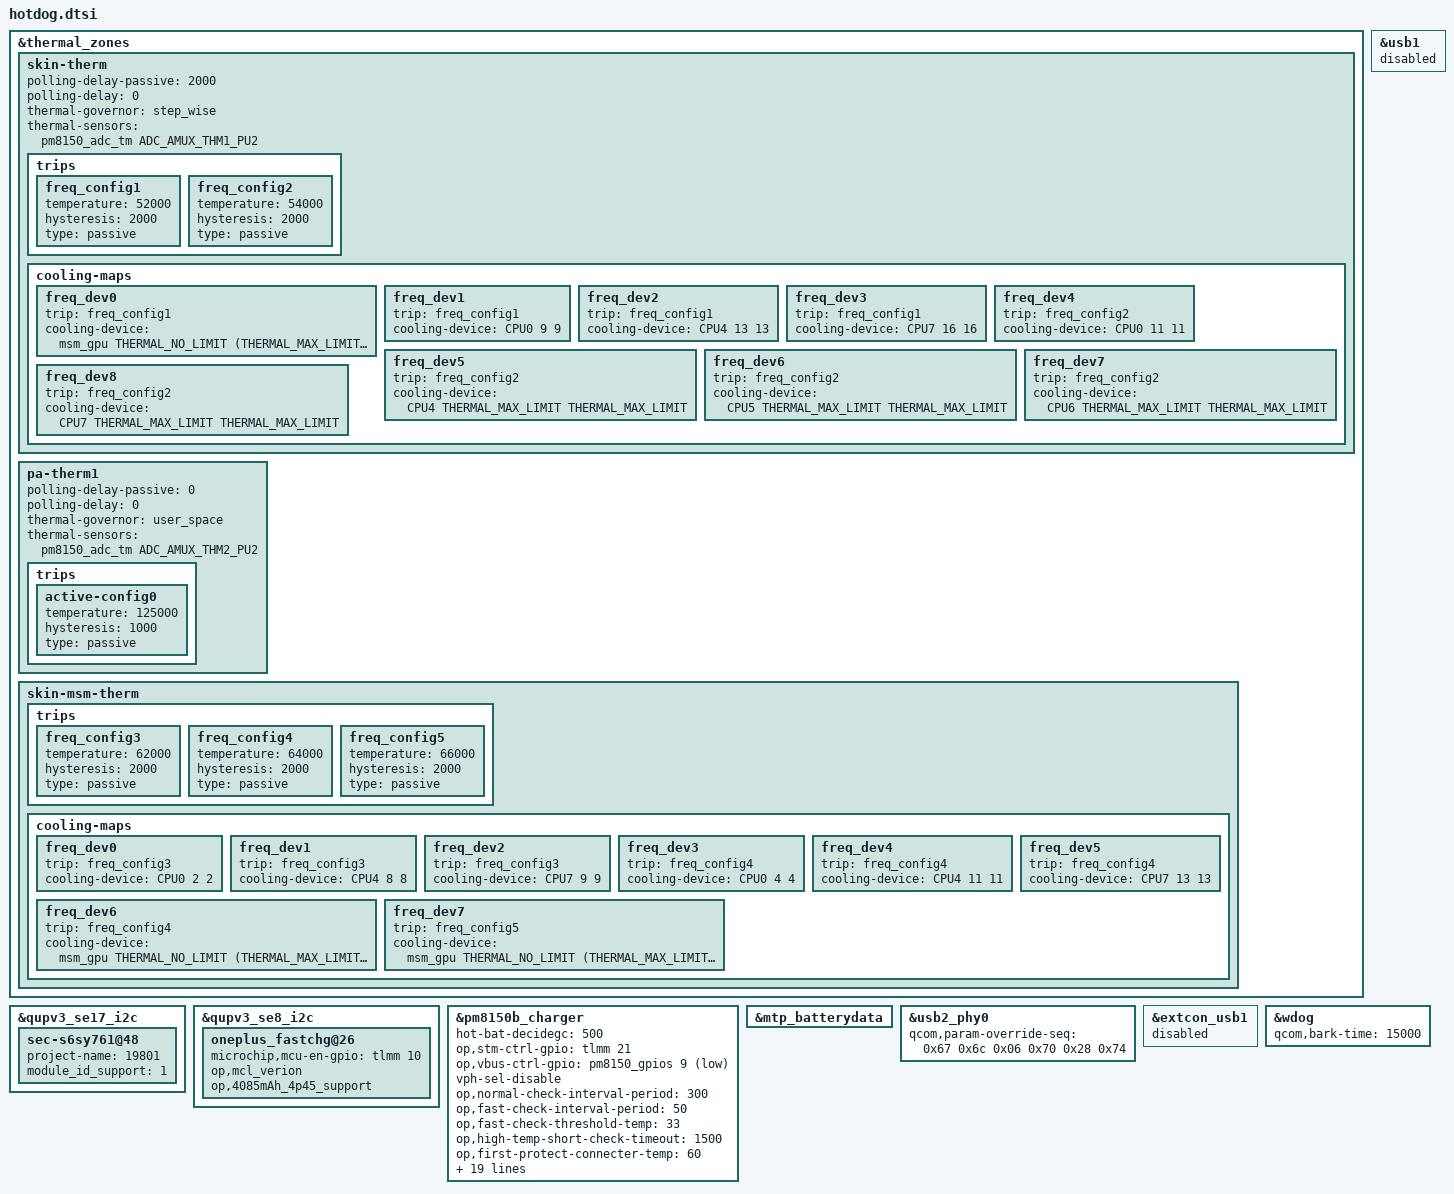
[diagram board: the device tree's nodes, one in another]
/*this is for different project dtsi*/
/* OnePlus add thermistor, by rio.zhao*/

&thermal_zones {
	skin-therm {
		polling-delay-passive = <2000>;
		polling-delay = <0>;
		thermal-governor = "step_wise";
		thermal-sensors = <&pm8150_adc_tm ADC_AMUX_THM1_PU2>;
		trips {
			freq_config1: freq_config1 {
				temperature = <52000>;
				hysteresis = <2000>;
				type = "passive";
			};
			freq_config2: freq_config2 {
				temperature = <54000>;
				hysteresis = <2000>;
				type = "passive";
			};
		};
		cooling-maps {
			freq_dev0 {
				trip = <&freq_config1>;
				cooling-device =
					<&msm_gpu THERMAL_NO_LIMIT
						(THERMAL_MAX_LIMIT-1)>;/*345*/
			};
			freq_dev1 {
				trip = <&freq_config1>;
				cooling-device =
					<&CPU0 9 9>;/*1036*/
			};
			freq_dev2 {
				trip = <&freq_config1>;
				cooling-device =
					<&CPU4 13 13>;/*1056*/
			};
			freq_dev3 {
				trip = <&freq_config1>;
				cooling-device =
					<&CPU7 16 16>;/*1171*/
			};
			freq_dev4 {
				trip = <&freq_config2>;
				cooling-device =
					<&CPU0 11 11>;/*844*/
			};
			freq_dev5 {
				trip = <&freq_config2>;
				cooling-device =
					<&CPU4 THERMAL_MAX_LIMIT
					THERMAL_MAX_LIMIT>;
			};
			freq_dev6 {
				trip = <&freq_config2>;
				cooling-device =
					<&CPU5 THERMAL_MAX_LIMIT
					THERMAL_MAX_LIMIT>;
			};
			freq_dev7 {
				trip = <&freq_config2>;
				cooling-device =
					<&CPU6 THERMAL_MAX_LIMIT
					THERMAL_MAX_LIMIT>;
			};
			freq_dev8 {
				trip = <&freq_config2>;
				cooling-device =
					<&CPU7 THERMAL_MAX_LIMIT
					THERMAL_MAX_LIMIT>;
			};
		};
	};

	pa-therm1 {
		polling-delay-passive = <0>;
		polling-delay = <0>;
		thermal-governor = "user_space";
		thermal-sensors = <&pm8150_adc_tm ADC_AMUX_THM2_PU2>;
		trips {
			active-config0 {
				temperature = <125000>;
				hysteresis = <1000>;
				type = "passive";
			};
		};
	};

	skin-msm-therm {
		trips {
			freq_config3: freq_config3 {
				temperature = <62000>;
				hysteresis = <2000>;
				type = "passive";
			};
			freq_config4: freq_config4 {
				temperature = <64000>;
				hysteresis = <2000>;
				type = "passive";
			};
			freq_config5: freq_config5 {
				temperature = <66000>;
				hysteresis = <2000>;
				type = "passive";
			};
		};
		cooling-maps {
			freq_dev0 {
				trip = <&freq_config3>;
				cooling-device =
					<&CPU0 2 2>;/*1632 18*/
			};
			freq_dev1 {
				trip = <&freq_config3>;
				cooling-device =
					<&CPU4 8 8>;/*1612 17*/
			};
			freq_dev2 {
				trip = <&freq_config3>;
				cooling-device =
					<&CPU7 9 9>;/*1920 20*/
			};
			freq_dev3 {
				trip = <&freq_config4>;
				cooling-device =
					<&CPU0 4 4>;/*1478*/
			};
			freq_dev4 {
				trip = <&freq_config4>;
				cooling-device =
					<&CPU4 11 11>;/*1286*/
			};
			freq_dev5 {
				trip = <&freq_config4>;
				cooling-device =
					<&CPU7 13 13>;/*1497*/
			};
			freq_dev6 {
				trip = <&freq_config4>;
				cooling-device =
					<&msm_gpu THERMAL_NO_LIMIT
						(THERMAL_MAX_LIMIT-3)>;/*499*/
			};
			freq_dev7 {
				trip = <&freq_config5>;
				cooling-device =
					<&msm_gpu THERMAL_NO_LIMIT
						(THERMAL_MAX_LIMIT-2)>;/*427*/
			};
		};
	};
};

&qupv3_se17_i2c {
	sec-s6sy761@48 {
		project-name = "19801";
		module_id_support = <1>;
	};
};

/* for Battery & Charging  STRAT */
&qupv3_se8_i2c {
	oneplus_fastchg@26{
		microchip,mcu-en-gpio = <&tlmm 10 0x00>;
		op,mcl_verion;
		op,4085mAh_4p45_support;
	};
};

&pm8150b_charger {
	/* for verify test adjust 530->500 */
	hot-bat-decidegc = <500>;
	/* for external ship mode suppot */
	op,stm-ctrl-gpio = <&tlmm 21 0x00>;
	op,vbus-ctrl-gpio = <&pm8150_gpios 9 GPIO_ACTIVE_LOW>;

	/*not need vph sel 300mv for LCD DCDC mode switch issue*/
	vph-sel-disable;

	/* for usb connecter temperature check */
	op,normal-check-interval-period = <300>;
	op,fast-check-interval-period = <50>;
	op,fast-check-threshold-temp = <33>;
	op,high-temp-short-check-timeout = <1500>;
	op,first-protect-connecter-temp = <60>;
	op,second-protect-connecter-temp = <45>;
	op,second-protect-interval-temp = <12>;
	op,third-protect-rise-rate = <3>;
	op,third-protect-loop-temp = <40>;
	op,third-protect-interval-temp = <8>;
	op,third-protect-base-temp = <20>;

	/* for charge current&voltage curve optimize */
	op,fv-offset-voltage-mv = <50>;

	/* skin thermal temp adjust the dash current */
	op,skin-thermal-high-threshold = <38>;
	op,skin-thermal-normal-threshold = <36>;
	op,enable-dash-current-dynamic-adjust;

	/* for 4p45v not charge full issue add sw full count numb */
	op,full-count-sw-numb = <2>;

	io-channels = <&pm8150b_vadc ADC_MID_CHG_DIV6>,
				<&pm8150b_vadc ADC_USB_IN_V_16>,
				<&pm8150b_vadc ADC_USB_IN_I>,
				<&pm8150b_vadc ADC_CHG_TEMP>,
				<&pm8150b_vadc ADC_AMUX_THM4_PU1>,
				<&pm8150_vadc ADC_AMUX_THM1_PU2>,
				<&pm8150b_vadc ADC_VPH_PWR>,
				<&pm8150b_vadc ADC_SBUx>;
	io-channel-names = "mid_voltage",
				"usb_in_voltage",
				"usb_in_current",
				"chg_temp",
				"gpio1_voltage",
				"skin_therm",
				"vph_voltage",
				"sbux_res";
};

&mtp_batterydata {
	#include "OP-fg-batterydata-4085mah.dtsi"
};
/* for Battery & Charging  END */

/* @bsp, 2019/7/23 usb config START*/
&usb2_phy0 {
	qcom,param-override-seq =
		<0x67 0x6c/*Disconnection voltage +21.56%*/
		 0x06 0x70/*Pre-emphasis:4x DC voltage level:+6.50%*/
		 0x28 0x74>;
};

&extcon_usb1 {
	status = "disabled";
};

&usb1 {
	status = "disabled";
};
/* @bsp, 2019/7/23 usb config END*/

&wdog{
	qcom,bark-time = <15000>;
};

